# M051AN_v1 register map
File version: 1.0
Registers are 32-bit, read-write, reset 0x0 unless marked. A register's access mark holds for its fields unless they carry their own. Offsets are from the block's base; [hi:lo] are bit positions; {n}, {i} and the like mark numbered series; 'fields as' and 'values as' point back to an identical list.

## CLK — CLK Register Map
Base 0x50000200
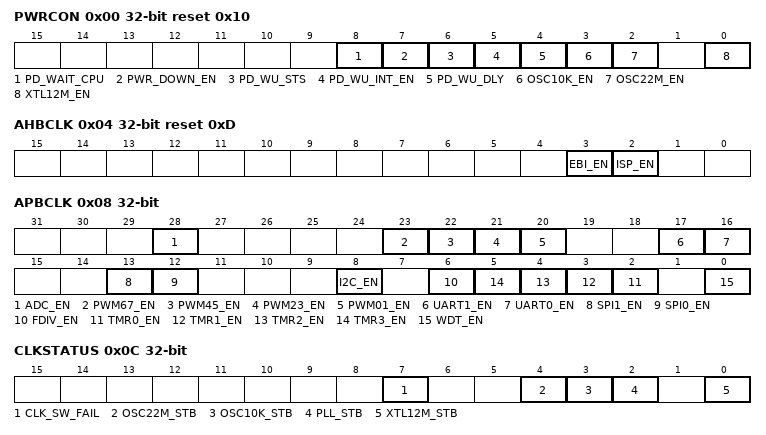
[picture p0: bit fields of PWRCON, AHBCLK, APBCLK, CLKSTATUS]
0x00 PWRCON reset 0x10 (reset mask 0xFFFFFFF0) — System Power Down Control Register
  [8] PD_WAIT_CPU — This Bit Control the Power Down Entry Condition (write-protection bit)
    0=Chip entry power down mode when the PWR_DOWN_EN bit is set to 1; 1=Chip enter power down mode when the both PD_WAIT_CPU and PWR_DOWN_EN bits are set to 1 and CPU run WFI instruction
  [7] PWR_DOWN_EN — System Power Down Enable Bit (write-protection bit). When this bit is set to 1, the chip power down mode is enabled and chip power down behavior will depends on the PD_WAIT_CPU bit (a) If the PD_WAIT_CPU is 0, then the chip enters power down mode immediately after the PWR_DOWN_EN bit set. (b) if the PD_WAIT_CPU is 1, then the chip keeps active till the CPU sleep mode is also active and then the chip enters power down mode. When chip wakes up from power down mode, this bit is auto cleared. Users need to set this bit again for next power down. When in power down mode, external 4~24 MHz high speed crystal and the internal 22.1184 MHz high speed oscillator will be disabled in this mode, but the internal 10 kHz low speed oscillator are not controlled by power down mode. When in power down mode, the PLL and system clock are disabled, and ignored the clock source selection. The clocks of peripheral are not controlled by power down mode, if the peripheral clock source is from internal 10 kHz low speed oscillator.
    0=Chip operating normally or chip in idle mode because of WFI command; 1=Chip enter the power down mode instant or wait CPU sleep command WFI
  [6] PD_WU_STS — Chip power down wake up status flag. Set by "power down wake up", it indicates that resume from power down mode" The flag is set if the GPIO(P0~P4), and UART wakeup. Write 1 to clear this bit to zero. Note: This bit is working only if PD_WU_INT_EN (PWRCON[5]) set to 1.
  [5] PD_WU_INT_EN — Power down mode wake Up Interrupt Enable (write-protected). The interrupt will occur when both PD_WU_STS and PD_WU_INT_EN are high.
    0=Disable; 1=Enable. The interrupt will occur when power down mode wake-up
  [4] PD_WU_DLY — Enable the wake up delay counter. (write-protected). When the chip wakes up from power down mode, the clock control will delay certain clock cycles to wait system clock stable. The delayed clock cycle is 4096 clock cycles when chip work at external 4~24 MHz high speed crystal, and 256 clock cycles when chip work at internal 22.1184 MHz high speed oscillator.
    0=Disable clock cycles delay; 1=Enable clock cycles delay
  [3] OSC10K_EN — Internal 10 kHz Low Speed Oscillator enable (write-protected)
    0=Internal 10 kHz low speed oscillator disable; 1=Internal 10 kHz low speed oscillator enable
  [2] OSC22M_EN — Internal 22.1184 MHz High Speed Oscillator enable (write-protected)
    0=Internal 22.1184 MHz high speed oscillator disable; 1=Internal 22.1184 MHz high speed oscillator enable
  [0] XTL12M_EN — External 4~24 MHz High Speed Crystal enable (write-protected). The bit default value is set by flash controller user configuration register config0 [26:24]. When the default clock source is from external 4~24 MHz high speed crystal, this bit is set to 1 automatically.
    0=External 4~24 MHz high speed crystal disable; 1=External 4~24 MHz high speed crystal enable
0x04 AHBCLK reset 0xD — AHB Devices Clock Enable Control Register
  [3] EBI_EN — EBI Controller Clock Enable Control.
    0=Disable the EBI controller clock; 1=Enable the EBI controller clock
  [2] ISP_EN — Flash ISP Controller Clock Enable Control.
    0=To disable the Flash ISP controller clock; 1=To enable the Flash ISP controller clock
0x08 APBCLK (reset mask 0xFFFFFFF0) — APB Devices Clock Enable Control Register
  [28] ADC_EN — Analog-Digital-Converter (ADC) Clock Enable
    0=Disable ADC clock; 1=Enable ADC clock
  [23] PWM67_EN — PWM_67 Clock Enable
    0=Disable PWM67 clock; 1=Enable PWM67 clock
  [22] PWM45_EN — PWM_45 Clock Enable
    0=Disable PWM45 clock; 1=Enable PWM45 clock
  [21] PWM23_EN — PWM_23 Clock Enable
    0=Disable PWM23 clock; 1=Enable PWM23 clock
  [20] PWM01_EN — PWM_01 Clock Enable
    0=Disable PWM01 clock; 1=Enable PWM01 clock
  [17] UART1_EN — UART1 Clock Enable
    0=Disable UART1 clock; 1=Enable UART1 clock
  [16] UART0_EN — UART0 Clock Enable
    0=Disable UART0 clock; 1=Enable UART0 clock
  [13] SPI1_EN — SPI1 Clock Enable
    0=Disable SPI1 Clock; 1=Enable SPI1 Clock
  [12] SPI0_EN — SPI0 Clock Enable
    0=Disable SPI0 Clock; 1=Enable SPI0 Clock
  [8] I2C_EN — I2C Clock Enable
    0=Disable I2C Clock; 1=Enable I2C Clock
  [6] FDIV_EN — Clock Divider Clock Enable
    0=Disable FDIV Clock; 1=Enable FDIV Clock
  [n+2] TMR{n}_EN (n=0..3) — Timer{n} Clock Enable
    0=Disable Timer{n} Clock; 1=Enable Timer{n} Clock
  [0] WDT_EN — Watchdog Timer Clock Enable. This bit is the protected bit. It means programming this needs to write "59h", "16h", "88h" to address 0x5000_0100 to disable register protection. Reference the register REGWRPROT at address GCR_BA+0x100.
    0=Disable Watchdog Timer Clock; 1=Enable Watchdog Timer Clock
0x0C CLKSTATUS (reset mask 0xFFFFFF00) — Clock Status Monitor Register
  [7] CLK_SW_FAIL — Clock Switch Fail Flag. This bit will be set when target switch clock source is not stable. Write 1 to clear this bit to zero.
    0=Clock switch if success; 1=Clock switch if fail
  [4] OSC22M_STB ro — Internal 22.1184 MHz High Speed Clock Source Stable Flag (Read Only)
    0=Internal 22.1184 MHz high speed oscillator clock is not stable or disable; 1=Internal 22.1184 MHz high speed oscillator clock is stable
  [3] OSC10K_STB ro — Internal 10 kHz Low Speed Clock Source Stable Flag (Read Only)
    0=Internal 10 kHz low speed oscillator clock is not stable or disable; 1=Internal 10 kHz low speed oscillator clock is stable
  [2] PLL_STB ro — PLL Clock Source Stable Flag (Read Only)
    0=PLL clock is not stable or disable; 1=PLL clock is stable
  [0] XTL12M_STB ro — External 4~24 MHz High Speed Crystal Clock Source Stable Flag (Read Only)
    0=External 4~24 MHz high speed crystal clock is not stable or disable; 1=External 4~24 MHz high speed crystal clock is stable
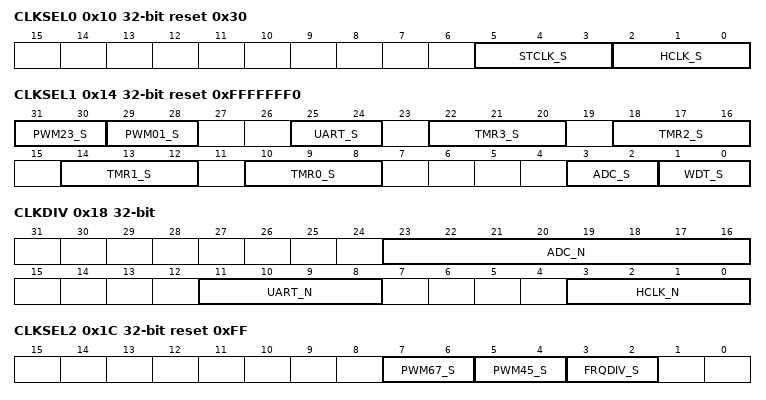
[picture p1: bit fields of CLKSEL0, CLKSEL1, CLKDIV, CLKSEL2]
0x10 CLKSEL0 reset 0x30 (reset mask 0xFFFFFFF0) — Clock Source Select Control Register 0
  [5:3] STCLK_S — MCU Cortex_M0 SysTick clock source select. This bit is the protected bit. It means programming this needs to write "59h", "16h", "88h" to address 0x5000_0100 to disable register protection. Reference the register REGWRPROT at address GCR_BA+0x100.
    0=Clock source from external 4~24 MHz high speed crystal clock; 1=Reserved. Clock source from internal 22.1184 MHz high speed oscillator clock/2; 2=Clock source from external 4~24 MHz high speed crystal clock/2; 3=Clock source from HCLK/2
  [2:0] HCLK_S — HCLK clock source select. Note: Before clock switching, the related clock sources (both pre-select and new-select) must be turn on. The 3-bit default value is reloaded from the value of CFOSC (Config0[26:24]) in user configuration register of Flash controller by any reset. Therefore the default value is either 000b or 111b. These bits are protected bit, It means programming this bit needs to write "59h", "16h", "88h" to address 0x5000_0100 to disable register protection. Reference the register REGWRPROT at address GCR_BA+0x100.
    0=Clock source from external 4~24 MHz high speed crystal clock; 1=Reserved. Clock source from internal 22.1184 MHz high speed oscillator clock; 2=Clock source from PLL clock; 3=Clock source from internal 10 kHz low speed oscillator clock
0x14 CLKSEL1 reset 0xFFFFFFF0 (reset mask 0xFFFFFFF0) — Clock Source Select Control Register 1
  [31:30] PWM23_S — PWM2 and PWM3 clock source select. PWM2 and PWM3 uses the same Engine clock source, both of them use the same pre-scalar
    0=Clock source from external 4~24 MHz high speed crystal clock; 2=Clock source from HCLK; 3=Clock source from internal 22.1184 MHz high speed oscillator clock
  [29:28] PWM01_S — PWM0 and PWM1 clock source select. PWM0 and PWM1 uses the same Engine clock source, both of them use the same pre-scalar
    values as PWM23_S
  [25:24] UART_S — UART clock source select.
    0=Clock source from external 4~24 MHz high speed crystal clock; 1=Clock source from PLL clock. Clock source from internal 22.1184 MHz high speed oscillator clock
  [4n+10:4n+8] TMR{n}_S (n=0..3) — TIMER{n} clock source select.
    0=Clock source from external 4~24 MHz high speed crystal clock; 1=Reserved. Clock source from internal 22.1184 MHz high speed oscillator clock; 2=Clock source from HCLK
  [3:2] ADC_S — ADC clock source select.
    values as UART_S
  [1:0] WDT_S — WDT clock source select. This bit is the protected bit. It means programming this needs to write "59h", "16h", "88h" to address 0x5000_0100 to disable register protection. Reference the register REGWRPROT at address GCR_BA+0x100.
    2=Clock source from HCLK/2048 clock; 3=Clock source from internal 10 kHz low speed oscillator clock
0x18 CLKDIV — Clock Divider Number Register
  [23:16] ADC_N — ADC clock divide number from ADC clock source
  [11:8] UART_N — UART clock divide number from UART clock source
  [3:0] HCLK_N — HCLK clock divide number from HCLK clock source
0x1C CLKSEL2 reset 0xFF — Clock Source Select Control Register 2
  [all] fields
    values as CLKSEL1.PWM23_S
  [7:6] PWM67_S — PWM6 and PWM7 clock source select. PWM6 and PWM7 used the same Engine clock source, both of them use the same pre-scalar
  [5:4] PWM45_S — PWM4 and PWM5 clock source select. PWM4 and PWM5 used the same Engine clock source, both of them use the same pre-scalar
  [3:2] FRQDIV_S — Clock Divider Clock Source Select
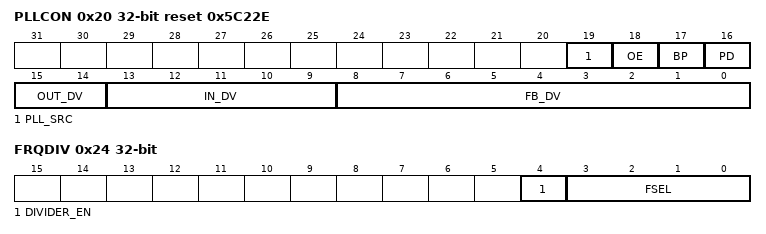
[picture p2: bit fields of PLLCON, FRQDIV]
0x20 PLLCON reset 0x5C22E — PLL Control Register
  [19] PLL_SRC — PLL Source Clock Select
    0=PLL source clock from external 4~24 MHz high speed crystal; 1=PLL source clock from internal 22.1184 MHz high speed oscillator
  [18] OE — PLL OE (FOUT enable) pin Control
    0=PLL FOUT enable; 1=PLL FOUT is fixed low
  [17] BP — PLL Bypass Control
    0=PLL is in normal mode (default); 1=PLL clock output is same as clock input (XTALin)
  [16] PD — Power Down Mode. If set the IDLE bit "1" in PWRCON register, the PLL will enter power down mode too
    0=PLL is in normal mode; 1=PLL is in power down mode (default)
  [15:14] OUT_DV — PLL Output Divider Control Pins
  [13:9] IN_DV — PLL Input Divider Control Pins
  [8:0] FB_DV — PLL Feedback Divider Control Pins
0x24 FRQDIV — Frequency Divider Control Register
  [4] DIVIDER_EN — Frequency Divider Enable Bit
    0=Disable Frequency Divider; 1=Enable Frequency Divider
  [3:0] FSEL — Divider Output Frequency Selection Bits. The formula of output frequency is. Fin is the input clock frequency. Fout is the frequency of divider output clock. N is the 4-bit value of FSEL[3:0].
